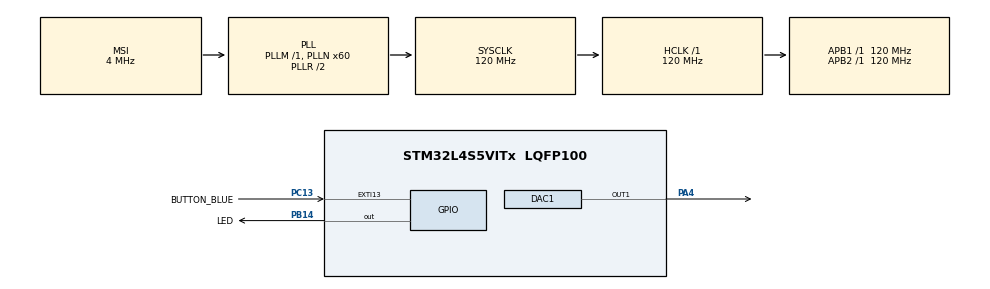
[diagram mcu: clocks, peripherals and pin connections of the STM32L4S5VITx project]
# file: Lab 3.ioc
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Mcu.Family=STM32L4
RCC.MSI_VALUE=4000000
RCC.CortexFreq_Value=120000000
Dma.DAC1_CH1.0.Priority=DMA_PRIORITY_LOW
PC13.Signal=GPXTI13
PB14.GPIO_Label=LED
PC13.GPIO_Label=BUTTON_BLUE
RCC.SYSCLKSource=RCC_SYSCLKSOURCE_PLLCLK
ProjectManager.StackSize=0x400
ProjectManager.TargetToolchain=STM32CubeIDE
Dma.DAC1_CH1.0.SyncPolarity=HAL_DMAMUX_SYNC_NO_EVENT
SH.COMP_DAC11_group.0=DAC1_OUT1,DAC_OUT1
RCC.HCLKFreq_Value=120000000
Dma.DAC1_CH1.0.EventEnable=DISABLE
RCC.APB2TimFreq_Value=120000000
RCC.USBFreq_Value=48000000
RCC.LSE_VALUE=32768
RCC.AHBFreq_Value=120000000
NVIC.EXTI15_10_IRQn=true\:0\:0\:false\:false\:true\:true\:true
PB14.Signal=GPIO_Output
RCC.HSE_VALUE=8000000
Dma.DAC1_CH1.0.MemDataAlignment=DMA_MDATAALIGN_HALFWORD
board=B-L4S5I-IOT01A
Dma.DAC1_CH1.0.SignalID=NONE
RCC.VCOOutputFreq_Value=240000000
RCC.APB2Freq_Value=120000000
VP_TIM2_VS_ClockSourceINT.Mode=Internal
Dma.DAC1_CH1.0.Mode=DMA_CIRCULAR
NVIC.TIM2_IRQn=true\:0\:0\:false\:false\:true\:true\:true
RCC.ADCFreq_Value=48000000
Dma.DAC1_CH1.0.PeriphDataAlignment=DMA_PDATAALIGN_HALFWORD
DAC1.DAC_Trigger-DAC_OUT1=DAC_TRIGGER_T2_TRGO
TIM2.Period=1000
Dma.DAC1_CH1.0.MemInc=DMA_MINC_ENABLE
Mcu.Name=STM32L4S5VITx
Dma.DAC1_CH1.0.SyncEnable=DISABLE
PA4.Signal=COMP_DAC11_group
RCC.SYSCLKFreq_VALUE=120000000
Mcu.Package=LQFP100
TIM2.Prescaler=0
ProjectManager.HeapSize=0x200
Dma.DAC1_CH1.0.Instance=DMA1_Channel1
RCC.HSI_VALUE=16000000
NVIC.PriorityGroup=NVIC_PRIORITYGROUP_4
TIM2.TIM_MasterOutputTrigger=TIM_TRGO_UPDATE
RCC.PLLN=60
RCC.APB1TimFreq_Value=120000000
Dma.DAC1_CH1.0.SyncRequestNumber=1
NVIC.DMA1_Channel1_IRQn=true\:0\:0\:false\:false\:true\:false\:true
Dma.DAC1_CH1.0.SyncSignalID=NONE
Dma.Request0=DAC1_CH1
RCC.APB1Freq_Value=120000000
Dma.DAC1_CH1.0.Direction=DMA_MEMORY_TO_PERIPH
Dma.DAC1_CH1.0.PeriphInc=DMA_PINC_DISABLE
Dma.DAC1_CH1.0.Polarity=HAL_DMAMUX_REQUEST_GEN_RISING
RCC.HSI48_VALUE=48000000
RCC.PLLSAI1N=24
Dma.DAC1_CH1.0.RequestNumber=1

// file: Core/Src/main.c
/* USER CODE BEGIN Header */
/**
  ******************************************************************************
  * @file           : main.c
  * @brief          : Main program body
  ******************************************************************************
  * @attention
  *
  * <h2><center>&copy; Copyright (c) 2021 STMicroelectronics.
  * All rights reserved.</center></h2>
  *
  * This software component is licensed by ST under BSD 3-Clause license,
  * the "License"; You may not use this file except in compliance with the
  * License. You may obtain a copy of the License at:
  *                        opensource.org/licenses/BSD-3-Clause
  *
  ******************************************************************************
  */
/* USER CODE END Header */
#include "main.h"

/* USER CODE BEGIN Includes */
#include "arm_math.h"
/* USER CODE END Includes */

/* USER CODE BEGIN PD */
#define SAWTOOTH
#define TRIANGLE
#define SINE
#define PART2
/* USER CODE END PD */

DAC_HandleTypeDef hdac1;
DMA_HandleTypeDef hdma_dac1_ch1;

TIM_HandleTypeDef htim2;

void SystemClock_Config(void);
static void MX_GPIO_Init(void);
static void MX_DMA_Init(void);
static void MX_DAC1_Init(void);
static void MX_TIM2_Init(void);

/* USER CODE BEGIN 0 */
uint16_t sawTooth, triangle;
uint32_t duration;
float frequencySaw, frequencyTri;

uint32_t sine2kHz_index = 0;
uint32_t sample_index = 0;

uint32_t *sineWaves[3]; //pointer to sineWave arrays
uint32_t no_samples_array[3] = {120, 60, 30};

float sine1kHz[120]; //variable to keep one period of DAC sine values
float sine2kHz[60];
float sine4kHz[30];

/* USER CODE END 0 */

int main(void)
{

  /* MCU Configuration--------------------------------------------------------*/

  /* Reset of all peripherals, Initializes the Flash interface and the Systick. */
  HAL_Init();

  /* Configure the system clock */
  SystemClock_Config();

  /* Initialize all configured peripherals */
  MX_GPIO_Init();
  MX_DMA_Init();
  MX_DAC1_Init();
  MX_TIM2_Init();
  /* USER CODE BEGIN 2 */

//  start Timer
  HAL_TIM_Base_Start_IT(&htim2);
  //Start DAC output channels
  HAL_DAC_Start(&hdac1, DAC_CHANNEL_1);

  /**----PART2 ------**/
  //Our clock frequency is 120MHz. TIM2 counter period is 1000
  //scaling 120 DAC samples for the channel when timer interrupts corresponds to
  //a sine period of 1khz as each sample gets read per 1ms.
  //Consequently, scaling 60 DAC samples for the channel -> 2khz sine wave

  	for (uint32_t i = 0; i < 120; i++) {
  	  sine1kHz[i] = (float)1365.0 * (1 + arm_sin_f32((float) (2*PI*i)/120));
  	  //vary DAC values over 2/3 of range ie (4095*2)/3 = 2730
  	  //(2730/2) = 1365
	}
	for (uint32_t i = 0; i < 60; i++) {
	  sine2kHz[i] = (float)1365.0 * (1 + arm_sin_f32((float) (2*PI*i)/60));
	}
	for (uint32_t i = 0; i < 30; i++) {
	  sine4kHz[i] = (float)1365.0 * (1 + arm_sin_f32((float) (2*PI*i)/30));
	}
	//*sineWave -> points to respective sine wave
    sineWaves[0] = sine1kHz;
    sineWaves[1] = sine2kHz;
    sineWaves[2] = sine4kHz;

  /* USER CODE END 2 */

  /* Infinite loop */
  /* USER CODE BEGIN WHILE */
  while (1)
  {
//Part 2 works with interrupts so while loop in this part should be empty
    /* USER CODE END WHILE */

  }
}

void SystemClock_Config(void)
{
  RCC_OscInitTypeDef RCC_OscInitStruct = {0};
  RCC_ClkInitTypeDef RCC_ClkInitStruct = {0};

  /** Configure the main internal regulator output voltage
  */
  if (HAL_PWREx_ControlVoltageScaling(PWR_REGULATOR_VOLTAGE_SCALE1_BOOST) != HAL_OK)
  {
    Error_Handler();
  }
  /** Initializes the RCC Oscillators according to the specified parameters
  * in the RCC_OscInitTypeDef structure.
  */
  RCC_OscInitStruct.OscillatorType = RCC_OSCILLATORTYPE_MSI;
  RCC_OscInitStruct.MSIState = RCC_MSI_ON;
  RCC_OscInitStruct.MSICalibrationValue = 0;
  RCC_OscInitStruct.MSIClockRange = RCC_MSIRANGE_6;
  RCC_OscInitStruct.PLL.PLLState = RCC_PLL_ON;
  RCC_OscInitStruct.PLL.PLLSource = RCC_PLLSOURCE_MSI;
  RCC_OscInitStruct.PLL.PLLM = 1;
  RCC_OscInitStruct.PLL.PLLN = 60;
  RCC_OscInitStruct.PLL.PLLP = RCC_PLLP_DIV2;
  RCC_OscInitStruct.PLL.PLLQ = RCC_PLLQ_DIV2;
  RCC_OscInitStruct.PLL.PLLR = RCC_PLLR_DIV2;
  if (HAL_RCC_OscConfig(&RCC_OscInitStruct) != HAL_OK)
  {
    Error_Handler();
  }
  /** Initializes the CPU, AHB and APB buses clocks
  */
  RCC_ClkInitStruct.ClockType = RCC_CLOCKTYPE_HCLK|RCC_CLOCKTYPE_SYSCLK
                              |RCC_CLOCKTYPE_PCLK1|RCC_CLOCKTYPE_PCLK2;
  RCC_ClkInitStruct.SYSCLKSource = RCC_SYSCLKSOURCE_PLLCLK;
  RCC_ClkInitStruct.AHBCLKDivider = RCC_SYSCLK_DIV1;
  RCC_ClkInitStruct.APB1CLKDivider = RCC_HCLK_DIV1;
  RCC_ClkInitStruct.APB2CLKDivider = RCC_HCLK_DIV1;

  if (HAL_RCC_ClockConfig(&RCC_ClkInitStruct, FLASH_LATENCY_5) != HAL_OK)
  {
    Error_Handler();
  }
}

static void MX_DAC1_Init(void)
{

  DAC_ChannelConfTypeDef sConfig = {0};

  /** DAC Initialization
  */
  hdac1.Instance = DAC1;
  if (HAL_DAC_Init(&hdac1) != HAL_OK)
  {
    Error_Handler();
  }
  /** DAC channel OUT1 config
  */
  sConfig.DAC_SampleAndHold = DAC_SAMPLEANDHOLD_DISABLE;
  sConfig.DAC_Trigger = DAC_TRIGGER_T2_TRGO;
  sConfig.DAC_HighFrequency = DAC_HIGH_FREQUENCY_INTERFACE_MODE_DISABLE;
  sConfig.DAC_OutputBuffer = DAC_OUTPUTBUFFER_ENABLE;
  sConfig.DAC_ConnectOnChipPeripheral = DAC_CHIPCONNECT_DISABLE;
  sConfig.DAC_UserTrimming = DAC_TRIMMING_FACTORY;
  if (HAL_DAC_ConfigChannel(&hdac1, &sConfig, DAC_CHANNEL_1) != HAL_OK)
  {
    Error_Handler();
  }

}

static void MX_TIM2_Init(void)
{

  TIM_ClockConfigTypeDef sClockSourceConfig = {0};
  TIM_MasterConfigTypeDef sMasterConfig = {0};

  htim2.Instance = TIM2;
  htim2.Init.Prescaler = 0;
  htim2.Init.CounterMode = TIM_COUNTERMODE_UP;
  htim2.Init.Period = 1000;
  htim2.Init.ClockDivision = TIM_CLOCKDIVISION_DIV1;
  htim2.Init.AutoReloadPreload = TIM_AUTORELOAD_PRELOAD_DISABLE;
  if (HAL_TIM_Base_Init(&htim2) != HAL_OK)
  {
    Error_Handler();
  }
  sClockSourceConfig.ClockSource = TIM_CLOCKSOURCE_INTERNAL;
  if (HAL_TIM_ConfigClockSource(&htim2, &sClockSourceConfig) != HAL_OK)
  {
    Error_Handler();
  }
  sMasterConfig.MasterOutputTrigger = TIM_TRGO_UPDATE;
  sMasterConfig.MasterSlaveMode = TIM_MASTERSLAVEMODE_DISABLE;
  if (HAL_TIMEx_MasterConfigSynchronization(&htim2, &sMasterConfig) != HAL_OK)
  {
    Error_Handler();
  }

}

static void MX_DMA_Init(void)
{

  /* DMA controller clock enable */
  __HAL_RCC_DMAMUX1_CLK_ENABLE();
  __HAL_RCC_DMA1_CLK_ENABLE();

  /* DMA interrupt init */
  /* DMA1_Channel1_IRQn interrupt configuration */
  HAL_NVIC_SetPriority(DMA1_Channel1_IRQn, 0, 0);
  HAL_NVIC_EnableIRQ(DMA1_Channel1_IRQn);

}

static void MX_GPIO_Init(void)
{
  GPIO_InitTypeDef GPIO_InitStruct = {0};

  /* GPIO Ports Clock Enable */
  __HAL_RCC_GPIOC_CLK_ENABLE();
  __HAL_RCC_GPIOA_CLK_ENABLE();
  __HAL_RCC_GPIOB_CLK_ENABLE();

  /*Configure GPIO pin Output Level */
  HAL_GPIO_WritePin(LED_GPIO_Port, LED_Pin, GPIO_PIN_RESET);

  /*Configure GPIO pin : BUTTON_BLUE_Pin */
  GPIO_InitStruct.Pin = BUTTON_BLUE_Pin;
  GPIO_InitStruct.Mode = GPIO_MODE_IT_RISING;
  GPIO_InitStruct.Pull = GPIO_NOPULL;
  HAL_GPIO_Init(BUTTON_BLUE_GPIO_Port, &GPIO_InitStruct);

  /*Configure GPIO pin : LED_Pin */
  GPIO_InitStruct.Pin = LED_Pin;
  GPIO_InitStruct.Mode = GPIO_MODE_OUTPUT_PP;
  GPIO_InitStruct.Pull = GPIO_NOPULL;
  GPIO_InitStruct.Speed = GPIO_SPEED_FREQ_LOW;
  HAL_GPIO_Init(LED_GPIO_Port, &GPIO_InitStruct);

  /* EXTI interrupt init*/
  HAL_NVIC_SetPriority(EXTI15_10_IRQn, 0, 0);
  HAL_NVIC_EnableIRQ(EXTI15_10_IRQn);

}

/* USER CODE BEGIN 4 */
void HAL_GPIO_EXTI_Callback(uint16_t GPIO_Pin) {
	HAL_GPIO_TogglePin(LED_GPIO_Port, LED_Pin);

	// stop previous DMA,
	HAL_DAC_Stop_DMA(&hdac1, DAC_CHANNEL_1);
	//start new DMA channel with new sinewave values
	HAL_DAC_Start_DMA(&hdac1, DAC_CHANNEL_1, sineWaves[sample_index],
					no_samples_array[sample_index], DAC_ALIGN_12B_R);
	//update index to navigate to next sinewave array (1khz -> 2khz -> 4khz ->...)
	sample_index = (sample_index + 1) % 3;
}

//Only needed for Step 1 and Step 2
void HAL_TIM_PeriodElapsedCallback(TIM_HandleTypeDef *htim) {
	HAL_DAC_SetValue(&hdac1, DAC_CHANNEL_1, DAC_ALIGN_12B_R, sine2kHz[sine2kHz_index]);
	sine2kHz_index = (sine2kHz_index + 1) % 60;
}
/* USER CODE END 4 */

void Error_Handler(void)
{
  __disable_irq();
  while (1)
  {
  }
}

/************************ (C) COPYRIGHT STMicroelectronics *****END OF FILE****/
